# I94100_v1_3 register map
File version: 1.0
Registers are 32-bit, read-write, reset 0x0 unless marked. A register's access mark holds for its fields unless they carry their own. Offsets are from the block's base; [hi:lo] are bit positions; {n}, {i} and the like mark numbered series; 'fields as' and 'values as' point back to an identical list.

## PDMA — PDMA Register Map
Base 0x40008000
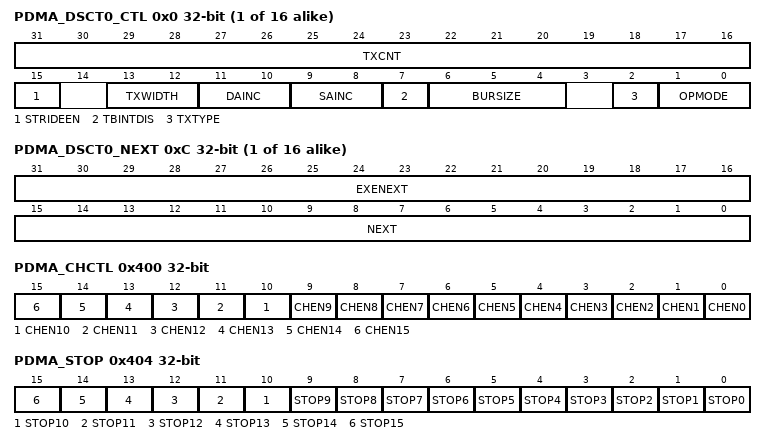
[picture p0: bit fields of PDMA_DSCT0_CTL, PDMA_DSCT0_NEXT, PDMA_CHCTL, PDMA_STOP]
{0x0+0x10*i} PDMA_DSCT{i}_CTL reset not defined (i=0..15) — Descriptor Table Control Register of PDMA Channel {i}
  [31:16] TXCNT — Transfer Count. The TXCNT represents the required number of PDMA transfer, the real transfer count is (TXCNT + 1); The maximum transfer count is 65536, every transfer may be byte, half-word or word that is dependent on TXWIDTH field. Note: When PDMA finish each transfer data, this field will be decrease immediately.
  [15] STRIDEEN — Stride Mode Enable Bit
    0=Stride transfer mode Disabled; 1=Stride transfer mode Enabled
  [13:12] TXWIDTH — Transfer Width Selection. This field is used for transfer width. Note: The PDMA transfer source address (PDMA_DSCT_SA) and PDMA transfer destination address (PDMA_DSCT_DA) should be alignment under the TXWIDTH selection
    0=One byte (8 bit) is transferred for every operation; 1=One half-word (16 bit) is transferred for every operation; 2=One word (32-bit) is transferred for every operation; 3=Reserved. Do not use
  [11:10] DAINC — Destination Address Increment. This field is used to set the destination address increment size.
    3=No increment (fixed address)
  [9:8] SAINC — Source Address Increment. This field is used to set the source address increment size.
    3=No increment (fixed address)
  [7] TBINTDIS — Table Interrupt Disable Bit. This field can be used to decide whether to enable table interrupt or not. This bit is only used for scatter-gather mode. If the TBINTDIS bit is enabled when PDMA controller finishes transfer task, it will not generates transfer done interrupt.
    0=Table interrupt Enabled; 1=Table interrupt Disabled
  [6:4] BURSIZE — Burst Size. This field is used for peripheral to determine the burst size or used for determine the re-arbitration size. Note: This field is only useful in burst transfer type.
    0=128 Transfers; 1=64 Transfers; 2=32 Transfers; 3=16 Transfers; 4=8 Transfers; 5=4 Transfers; 6=2 Transfers; 7=1 Transfers
  [2] TXTYPE — Transfer Type
    0=Burst transfer type; 1=Single transfer type
  [1:0] OPMODE — PDMA Operation Mode Selection. Note: Before filling transfer task in the Descriptor Table, user must check if the descriptor table is complete.
    0=Idle state: Channel is stopped or this table is complete, when PDMA finish channel table task, OPMODE will be cleared to idle state automatically; 1=Basic mode: The descriptor table only has one task. When this task is finished, the PDMA_INTSTS[n] will be asserted; 2=Scatter-Gather mode: When operating in this mode, user must give the next descriptor table address in PDMA_DSCT_NEXT register; PDMA controller will ignore this task, then load the next task to execute; 3=Reserved. Do not use
{0x4+0x10*i} PDMA_DSCT{i}_SA reset not defined (i=0..15) — Source Address Register of PDMA Channel {i}
  [31:0] SA — PDMA Transfer Source Address Register. This field indicates a 32-bit source address of PDMA controller.
{0x8+0x10*i} PDMA_DSCT{i}_DA reset not defined (i=0..15) — Destination Address Register of PDMA Channel {i}
  [31:0] DA — PDMA Transfer Destination Address Register. This field indicates a 32-bit destination address of PDMA controller.
{0xC+0x10*i} PDMA_DSCT{i}_NEXT reset not defined (i=0..15) — First Scatter-gather Descriptor Table Offset Address of PDMA Channel {i}
  [31:16] EXENEXT — PDMA Execution Next Descriptor Table Offset. This field indicates the offset of next descriptor table address of current execution descriptor table in system memory. Note: write operation is useless in this field.
  [15:0] NEXT — PDMA Next Descriptor Table Offset. This field indicates the offset of the next descriptor table address in system memory. Write Operation: If the system memory based address is 0x2000_0000 (PDMA_SCATBA), and the next descriptor table is start from 0x2000_0100, then this field must fill in 0x0100. Read Operation: When operating in scatter-gather mode, the last two bits NEXT[1:0] will become reserved, and indicate the first next address of system memory. Note 1: The first descriptor table address must be word boundary. Note 2: Before filled transfer task in the descriptor table, user must check if the descriptor table is complete. Note 3: The address of descriptor tables must be in the same 64KB area.
{0x100+4i} PDMA_CURSCAT{i} ro reset not defined (i=0..15) — Current Scatter-gather Descriptor Table Address of PDMA Channel {i}
  [31:0] CURADDR — PDMA Current Description Address Register (Read Only). This field indicates a 32-bit current external description address of PDMA controller. Note: This field is read only and only used for Scatter-Gather mode to indicate the current external description address.
0x400 PDMA_CHCTL — PDMA Channel Control Register
  [n] CHEN{n} (n=10..15) — PDMA Channel {n} Enable Bit. Set this bit to 1 to enable PDMA channel {n} operation. Channel {n} cannot be active if it is not set as enabled. Note: Set corresponding bit of PDMA_STOP or PDMA_CHRST register will also clear this bit.
    0=PDMA Channel {n} Disabled; 1=PDMA Channel {n} Enabled
  [9] CHEN9 — PDMA Channel 9 Enable Bit. Set this bit to 1 to enable PDMA channel 9 operation. Channel 9 cannot be active if it is not set as enabled. Note: Set corresponding bit of PDMA_STOP or PDMA_CHRST register will also clear this bit.
    0=PDMA channel 9 Disabled; 1=PDMA channel 9 Enabled
  [n] CHEN{n} (n=0..8) — PDMA Channel {n} Enable Bit. Set this bit to 1 to enable PDMA channel {n} operation. Channel {n} cannot be active if it is not set as enabled. Note: Set corresponding bit of PDMA_STOP or PDMA_CHRST register will also clear this bit.
    0=PDMA Channel {n} Disabled; 1=PDMA Channel {n} Enabled
0x404 PDMA_STOP wo — PDMA Transfer Stop Control Register
  [n] STOP{n} (n=0..15) — PDMA Channel {n} Transfer Stop Control Register (Write Only). User can set this bit to stop the PDMA channel {n} transfer. When user sets STOP{n} bit, the PDMA controller will stop the on-going transfer, then clear the channel enable bit CHEN{n} (PDMA_CHCTL [{n}]) and clear request active flag. If re-enable the stopped channel again, the remaining transfers will be processed.
    0=No effect; 1=Stop PDMA channel {n} transfer
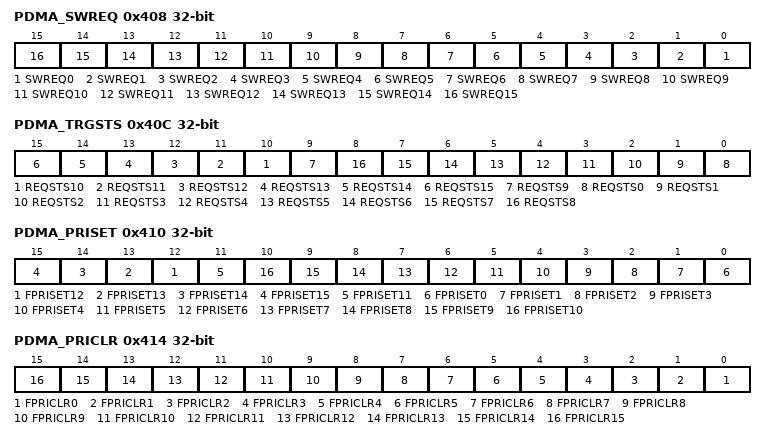
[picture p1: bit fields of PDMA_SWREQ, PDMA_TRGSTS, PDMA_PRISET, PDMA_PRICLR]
0x408 PDMA_SWREQ wo — PDMA Software Request Register
  [n] SWREQ{n} (n=0..15) — PDMA Channel {n} Software Request Register (Write Only). Set this bit to 1 to generate a software request to PDMA Channel {n}. Note1: User can read PDMA_TRGSTS register to know which channel is on active. Active flag may be triggered by software request or peripheral request. Note2: If user does not enable corresponding PDMA channel, the software request will be ignored.
    0=PDMA Channel {n} no effect; 1=PDMA Channel {n} generate a software request
0x40C PDMA_TRGSTS ro — PDMA Channel Request Status Register
  [n] REQSTS{n} (n=10..15) — PDMA Channel {n} Request Status (Read Only). This flag indicates whether channel {n} have a request or not, no matter request from software or peripheral. When PDMA controller finishes channel transfer, this bit will be cleared automatically. Note: If user stops or resets each PDMA transfer by setting PDMA_STOP or PDMA_CHRST register respectively, this bit will be cleared automatically after finishing current transfer.
    0=PDMA Channel {n} has no request; 1=PDMA Channel {n} has a request
  [9] REQSTS9 — PDMA Channel 9 Request Status (Read Only). This flag indicates whether channel 9 have a request or not, no matter request from software or peripheral. When PDMA controller finishes channel transfer, this bit will be cleared automatically. Note1: If user stops or resets each PDMA transfer by setting PDMA_STOP or PDMA_CHRST register respectively, this bit will be cleared automatically after finishing current transfer.
    0=PDMA Channel 9 has no request; 1=PDMA Channel 9 has a request
  [n] REQSTS{n} (n=0..8) — PDMA Channel {n} Request Status (Read Only). This flag indicates whether channel {n} have a request or not, no matter request from software or peripheral. When PDMA controller finishes channel transfer, this bit will be cleared automatically. Note: If user stops or resets each PDMA transfer by setting PDMA_STOP or PDMA_CHRST register respectively, this bit will be cleared automatically after finishing current transfer.
    values as REQSTS10
0x410 PDMA_PRISET — PDMA Fixed Priority Setting Register
  [n] FPRISET{n} (n=12..15) — PDMA Channel {n} Fixed Priority Setting Register. Set this bit to 1 to enable fixed priority level. Write Operation: Note: This field only set to fixed priority, clear fixed priority use PDMA_PRICLR register.
    0=No effect. Corresponding PDMA channel {n} is round-robin priority; 1=Set PDMA channel {n} to fixed priority channel. Corresponding PDMA channel {n} is fixed priority
  [11] FPRISET11 — PDMA Channel 10 Fixed Priority Setting Register. Set this bit to 1 to enable fixed priority level. Write Operation: Note: This field only set to fixed priority, clear fixed priority use PDMA_PRICLR register.
    0=No effect. Corresponding PDMA channel 11 is round-robin priority; 1=Set PDMA channel 11 to fixed priority channel. Corresponding PDMA channel 11 is fixed priority
  [n] FPRISET{n} (n=0..10) — PDMA Channel {n} Fixed Priority Setting Register. Set this bit to 1 to enable fixed priority level. Write Operation: Note: This field only set to fixed priority, clear fixed priority use PDMA_PRICLR register.
    values as FPRISET12
0x414 PDMA_PRICLR wo — PDMA Fixed Priority Clear Register
  [n] FPRICLR{n} (n=0..15) — PDMA Channel {n} Fixed Priority Clear Register (Write Only). Set this bit to 1 to clear fixed priority level. Note: User can read PDMA_PRISET register to know the channel priority.
    0=No effect; 1=Clear PDMA channel {n} fixed priority setting
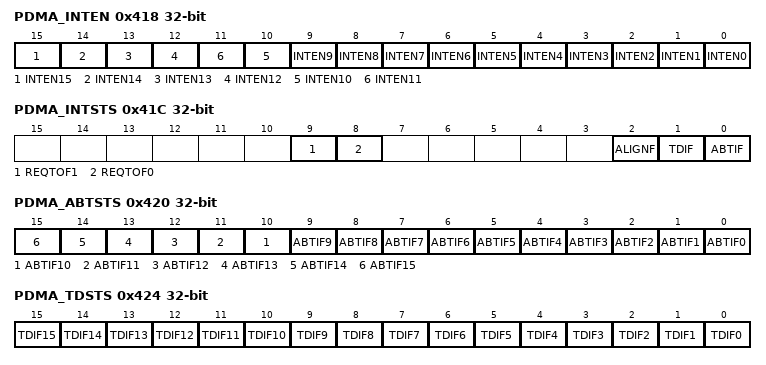
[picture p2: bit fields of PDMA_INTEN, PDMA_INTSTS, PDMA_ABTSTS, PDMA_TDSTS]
0x418 PDMA_INTEN — PDMA Interrupt Enable Register
  [15] INTEN15 — PDMA Channel 15 Interrupt Enable Register. This field is used for enabling PDMA channel 15 interrupt.
    0=PDMA channel 15 interrupt Disabled; 1=PDMA channel 15 interrupt Enabled
  [14] INTEN14 — PDMA Channel 14 Interrupt Enable Register. This field is used for enabling PDMA channel 14 interrupt.
    0=PDMA channel 14 interrupt Disabled; 1=PDMA channel 14 interrupt Enabled
  [13] INTEN13 — PDMA Channel 13 Interrupt Enable Register. This field is used for enabling PDMA channel 13 interrupt.
    0=PDMA channel 13 interrupt Disabled; 1=PDMA channel 13 interrupt Enabled
  [12] INTEN12 — PDMA Channel 0 Interrupt Enable Register. This field is used for enabling PDMA channel 12 interrupt.
    0=PDMA channel 12 interrupt Disabled; 1=PDMA channel 12 interrupt Enabled
  [n] INTEN{n} (n=0..11) — PDMA Channel {n} Interrupt Enable Register. This field is used for enabling PDMA channel {n} interrupt.
    0=PDMA channel {n} interrupt Disabled; 1=PDMA channel {n} interrupt Enabled
0x41C PDMA_INTSTS — PDMA Interrupt Status Register
  [9] REQTOF1 — Request Time-out Flag for Channel 1. This flag indicates that PDMA controller has waited peripheral request for a period defined by PDMA_TOC1, user can write 1 to clear these bits.
    0=No request time-out; 1=Peripheral request time-out
  [8] REQTOF0 — Request Time-out Flag for Channel 0. This flag indicates that PDMA controller has waited peripheral request for a period defined by PDMA_TOC0, user can write 1 to clear these bits.
    0=No request time-out; 1=Peripheral request time-out
  [2] ALIGNF ro — Transfer Alignment Interrupt Flag (Read Only)
    0=PDMA channel source address and destination address both follow transfer width setting; 1=PDMA channel source address or destination address is not follow transfer width setting
  [1] TDIF ro — Transfer Done Interrupt Flag (Read Only). This bit indicates that PDMA controller has finished transmission; User can read PDMA_TDSTS register to indicate which channel finished transfer.
    0=Not finished yet; 1=PDMA channel has finished transmission
  [0] ABTIF — PDMA Read/Write Target Abort Interrupt Flag (Read-only). This bit indicates that PDMA has target abort error; Software can read PDMA_ABTSTS register to find which channel has target abort error.
    0=No AHB bus ERROR response received; 1=AHB bus ERROR response received
0x420 PDMA_ABTSTS — PDMA Channel Read/Write Target Abort Flag Register
  [n] ABTIF{n} (n=0..15) — PDMA Channel {n} Read/Write Target Abort Interrupt Status Flag. This bit indicates PDMA channel {n} has target abort error; User can write 1 to clear these bits.
    0=No AHB bus ERROR response received when channel {n} transfer; 1=AHB bus ERROR response received when channel {n} transfer
0x424 PDMA_TDSTS — PDMA Channel Transfer Done Flag Register
  [n] TDIF{n} (n=0..15) — PDMA Channel {n} Transfer Done Flag Register. This bit indicates PDMA channel {n} transfer has been finished or not, user can write 1 to clear this bits.
    0=PDMA channel {n} transfer has not finished; 1=PDMA channel {n} has finished transmission
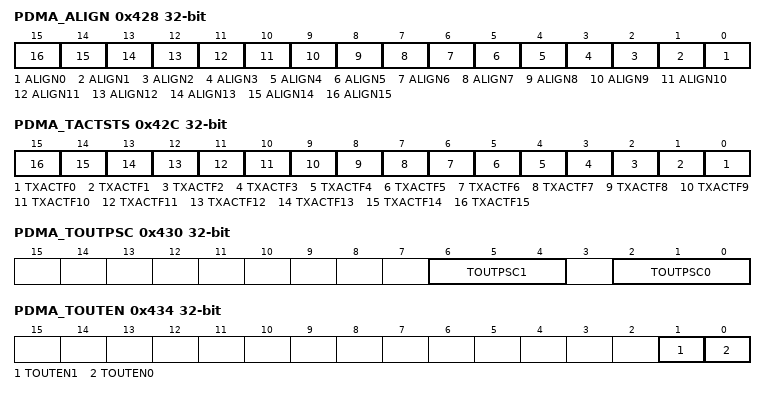
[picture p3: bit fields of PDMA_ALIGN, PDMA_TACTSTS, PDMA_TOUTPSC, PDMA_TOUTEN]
0x428 PDMA_ALIGN — PDMA Transfer Alignment Status Register
  [n] ALIGN{n} (n=0..15) — PDMA Channel {n} Transfer Alignment Flag Register. Note: Software can write 1 to clear this bit.
    0=PDMA channel {n} source address and destination address both follow transfer width setting; 1=PDMA channel {n} source address or destination address is not follow transfer width setting
0x42C PDMA_TACTSTS ro — PDMA Transfer Active Flag Register
  [n] TXACTF{n} (n=0..15) — PDMA Channel {n} Transfer on Active Flag Register (Read Only)
    0=PDMA channel {n} is not finished; 1=PDMA channel {n} is in active
0x430 PDMA_TOUTPSC — PDMA Time-out Prescaler Register
  [6:4] TOUTPSC1 — PDMA Channel 1 Time-out Clock Source Prescaler Bits
    0=PDMA channel 1 time-out clock source is HCLK/28; 1=PDMA channel 1 time-out clock source is HCLK/29; {v}=PDMA channel 1 time-out clock source is HCLK/{v+208} (v=2..7)
  [2:0] TOUTPSC0 — PDMA Channel 0 Time-out Clock Source Prescaler Bits
    0=PDMA channel 0 time-out clock source is HCLK/28; 1=PDMA channel 0 time-out clock source is HCLK/29; {v}=PDMA channel 0 time-out clock source is HCLK/{v+208} (v=2..7)
0x434 PDMA_TOUTEN — PDMA Time-out Enable Register
  [1] TOUTEN1 — PDMA Channel 1 Time-out Enable Bit
    0=PDMA Channel 1 time-out function Disable; 1=PDMA Channel 1 time-out function Enable
  [0] TOUTEN0 — PDMA Channel 0 Time-out Enable Bit
    0=PDMA Channel 0 time-out function Disable; 1=PDMA Channel 0 time-out function Enable
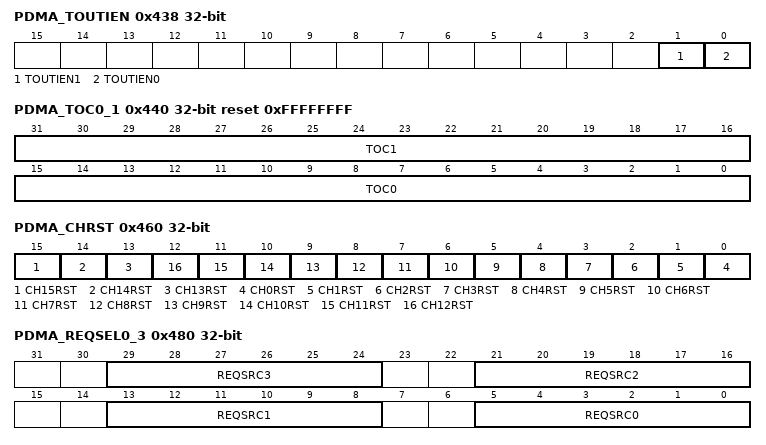
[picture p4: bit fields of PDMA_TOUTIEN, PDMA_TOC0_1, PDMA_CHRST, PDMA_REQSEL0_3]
0x438 PDMA_TOUTIEN — PDMA Time-out Interrupt Enable Register
  [1] TOUTIEN1 — PDMA Channel 1 Time-out Interrupt Enable Bit
    0=PDMA Channel 1 time-out interrupt Disable; 1=PDMA Channel 1 time-out interrupt Enable
  [0] TOUTIEN0 — PDMA Channel 0 Time-out Interrupt Enable Bit
    0=PDMA Channel 0 time-out interrupt Disable; 1=PDMA Channel 0 time-out interrupt Enable
0x43C PDMA_SCATBA reset 0x20000000 — PDMA Scatter-gather Descriptor Table Base Address Register
  [31:16] SCATBA — PDMA Scatter-gather Descriptor Table Address Register. In Scatter-Gather mode, this is the base address for calculating the next link - list address. The next link address equation is. Note: Only useful in Scatter-Gather mode.
0x440 PDMA_TOC0_1 reset 0xFFFFFFFF — PDMA Time-out Counter Ch1 and Ch0 Register
  [31:16] TOC1 — Time-out Counter for Channel 1. This controls the period of time-out function for channel 1. The calculation unit is based on the setting of TOUTPSC1.
  [15:0] TOC0 — Time-out Counter for Channel 0. This controls the period of time-out function for channel 0. The calculation unit is based on the setting of TOUTPSC0.
0x460 PDMA_CHRST — PDMA Channel Reset Register
  [15] CH15RST — Channel 15 Reset. Note 1: This bit will be cleared automatically after finishing reset. Note 2 : Set this bit to 1 will also clear corresponding bit of PDMA_CHCTL.
    0=corresponding channel 15 not reset; 1=corresponding channel 15 is reset
  [14] CH14RST — Channel 14 Reset. Note 1: This bit will be cleared automatically after finishing reset. Note 2 : Set this bit to 1 will also clear corresponding bit of PDMA_CHCTL.
    0=corresponding channel 14 not reset; 1=corresponding channel 14 is reset
  [13] CH13RST — Channel 13 Reset. Note 1 : This bit will be cleared automatically after finishing reset. Note 2 : Set this bit to 1 will also clear corresponding bit of PDMA_CHCTL.
    0=corresponding channel 13 not reset; 1=corresponding channel 13 is reset
  [n] CH{n}RST (n=0..12) — Channel {n} Reset. Note 1: This bit will be cleared automatically after finishing reset. Note 2 : Set this bit to 1 will also clear corresponding bit of PDMA_CHCTL.
    0=corresponding channel {n} not reset; 1=corresponding channel {n} is reset
0x480 PDMA_REQSEL0_3 — PDMA Request Source Select Register 0
  [29:24] REQSRC3 — Channel 3 Request Source Selection. This filed defines which peripheral is connected to PDMA channel 3. User can configure the peripheral setting by REQSRC3. Note: The channel configuration is the same as REQSRC0 field. Please refer to the explanation of REQSRC0.
  [21:16] REQSRC2 — Channel 2 Request Source Selection. This filed defines which peripheral is connected to PDMA channel 2. User can configure the peripheral setting by REQSRC2. Note: The channel configuration is the same as REQSRC0 field. Please refer to the explanation of REQSRC0.
  [13:8] REQSRC1 — Channel 1 Request Source Selection. This filed defines which peripheral is connected to PDMA channel 1. User can configure the peripheral setting by REQSRC1. Note: The channel configuration is the same as REQSRC0 field. Please refer to the explanation of REQSRC0.
  [5:0] REQSRC0 — Channel 0 Request Source Selection. This filed defines which peripheral is connected to PDMA channel 0. User can configure the peripheral by setting REQSRC0. Note 1: A peripheral can't assign to two channels at the same time. Note 2: This field is useless when transfer between memory and memory.
    0=Disable PDMA peripheral request; 4=Channel connects to UART0_TX; 5=Channel connects to UART0_RX; 20=Channel connects to SPI0_TX; 21=Channel connects to SPI0_RX; 22=Channel connects to SPI1_TX; 23=Channel connects to SPI1_RX; 24=Channel connects to SPI2_TX; 25=Channel connects to SPI2_RX; 27=Channel connects to DMIC_RX; 28=Channel connects to DPWM_TX; 32=Channel connects to PWM0_P1_RX; 33=Channel connects to PWM0_P2_RX; 34=Channel connects to PWM0_P3_RX; 44=Channel connects to I2S0_TX; 45=Channel connects to I2S0_RX; {v}=Channel connects to TMR{v-46} (v=46..49); 50=Channel connects to ADC_RX
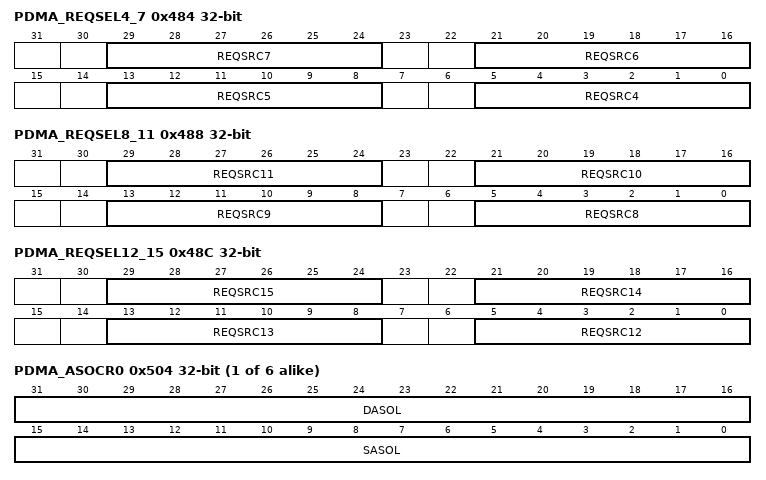
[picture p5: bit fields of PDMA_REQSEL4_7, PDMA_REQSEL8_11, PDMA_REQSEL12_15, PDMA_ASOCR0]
0x484 PDMA_REQSEL4_7 — PDMA Request Source Select Register 1
  [8n-27:8n-32] REQSRC{n} (n=4..7) — Channel {n} Request Source Selection. This filed defines which peripheral is connected to PDMA channel {n}. User can configure the peripheral setting by REQSRC{n}. Note: The channel configuration is the same as REQSRC0 field. Please refer to the explanation of REQSRC0.
0x488 PDMA_REQSEL8_11 — PDMA Request Source Select Register 2
  [29:24] REQSRC11 — Channel 11 Request Source Selection. This filed defines which peripheral is connected to PDMA channel 11. User can configure 1the peripheral setting by REQSRC11. Note: The channel configuration is the same as REQSRC0 field. Please refer to the explanation of REQSRC0.
  [21:16] REQSRC10 — Channel 10 Request Source Selection. This filed defines which peripheral is connected to PDMA channel 10. User can configure the peripheral setting by REQSRC10. Note: The channel configuration is the same as REQSRC0 field. Please refer to the explanation of REQSRC0.
  [13:8] REQSRC9 — Channel 9 Request Source Selection. This filed defines which peripheral is connected to PDMA channel 9. User can configure the peripheral setting by REQSRC9. Note: The channel configuration is the same as REQSRC0 field. Please refer to the explanation of REQSRC0.
  [5:0] REQSRC8 — Channel 8 Request Source Selection. This filed defines which peripheral is connected to PDMA channel 8. User can configure the peripheral setting by REQSRC8. Note: The channel configuration is the same as REQSRC.0 field. Please refer to the explanation of REQSRC0.
0x48C PDMA_REQSEL12_15 — PDMA Request Source Select Register 3
  [8n-91:8n-96] REQSRC{n} (n=12..15) — Channel {n-8} Request Source Selection. This filed defines which peripheral is connected to PDMA channel {n}. User can configure the peripheral setting by REQSRC{n}. Note: The channel configuration is the same as REQSRC0 field. Please refer to the explanation of REQSRC0.
{0x500+8i} PDMA_STCR{i} (i=0..5) — Stride Transfer Count Register of PDMA Channel {i}
  [15:0] STC — PDMA Stride Transfer Count
{0x504+8i} PDMA_ASOCR{i} (i=0..5) — Address Stride Offset Register of PDMA Channel {i}
  [31:16] DASOL — PDMA Destination Address Stride Offset Length. The 16-bit register defines the destination address stride transfer offset count of each row.
  [15:0] SASOL — PDMA Source Address Stride Offset Length. The 16-bit register defines the source address stride transfer offset count of each row.
